# hpb_reva register map
Registers are access not given, no defined reset value unless marked. A register's access mark holds for its fields unless they carry their own. Offsets are from the block's base; lines under a group give offsets from that group; [hi:lo] are bit positions; {n}, {i} and the like mark numbered series; 'fields as' and 'values as' point back to an identical list; <NAME> marks a mode.

## Memory map
0x40039000 HPB size 0x1000 — HyperBus Memory Controller Registers

## HPB — HyperBus Memory Controller Registers
Base 0x40039000
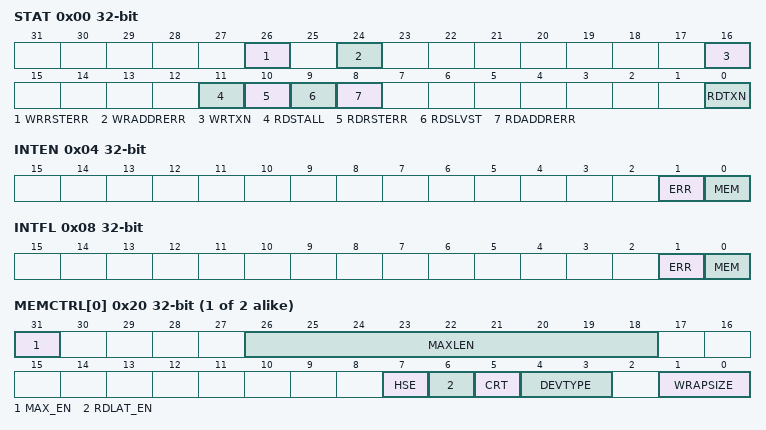
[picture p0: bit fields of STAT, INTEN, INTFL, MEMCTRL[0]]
0x00 STAT — Hyperbus Status Register.
  [26] WRRSTERR — Reset During Write Error. If this field is set a reset orrcured during a write.
    0=normal_op (No error.); 1=err (Memory controller was reset during write operation.)
  [24] WRADDRERR — Write Address Error. If this field is set a write address error orrcured.
    0=normal_op (No error.); 1=err (The write address to external memory is invalid.)
  [16] WRTXN — Write Transaction in Progress
    0=No write transaction currently in progress; 1=Write transaction currently in progress
  [11] RDSTALL — Read Data Stall.
    0=normal_op (Memory Controller operating normally.); 1=stalled (Read transaction is stalled because RDS is low (stalled).)
  [10] RDRSTERR — Reset During Read Error. If this field is set a reset orrcured during a read.
    0=normal_op (No error.); 1=err (Memory controller was reset during read operation.)
  [9] RDSLVST — Read Slave Status.
  [8] RDADDRERR — Read Address Error
    0=normal_op (No error.); 1=err (External read address not responding.)
  [0] RDTXN — Read Transaction in Progress
    0=No read transaction currently in progress; 1=Read transaction currently in progress
0x04 INTEN — Hyperbus Interrupt Enable Register.
  [1] ERR — Enables/disables the HPB error interrupt.
    0=dis (Disable error interrupt.); 1=en (Enable error interrupt.)
  [0] MEM — Hyperbus Memory Interrupt Enable.
    0=dis (Disable interrupt.); 1=en (Enable interrupt.)
0x08 INTFL — Hyperbus Interrupt Flag Register.
  [1] ERR — Error interrupt status flag.
    0=noint (Error interrupt not active.); 1=pending (Error interrupt currently pending.)
  [0] MEM — Hyperbus Memory Status Flag.
    0=noint (Memory interrupt not active.); 1=pending (Memory interrupt currently pending.)
{0x10+4i} MEMBADDR[{i}] (i=0..1) — Hyperbus Memory Base Address Register.
  [31:0] ADDR — Memory base address. This sets the base address of the addressable memory region where the port is mapped. Each address space is 512Mbytes. The lower 24 bits are read only and will always read 0.
{0x20+4i} MEMCTRL[{i}] (i=0..1) — Hyperbus Memory Control Register.
  [31] MAX_EN — Maximum CS# Length Enable.
    0=dis (No configured CS# low time.); 1=en (CS# low time is configured.)
  [26:18] MAXLEN — Maximum Read/Write. Set this field to the CS# low time in terms of clock cycles.
  [7] HSE — Xccela Half Sleep Exit. When half sleep exit is enabled, the CS# line is held low for ten clock cycles. This bit is automatically cleared by hardware when a Half Sleep Exit completes.
    0=dis (Half Sleep Exit disabled.); 1=en (Half Sleep Exit enabled.)
  [6] RDLAT_EN — Xccela Fixed Read Latency Enable. Set this bit to enable Xccela bus Fixed Read Latency. Set this field to match the latency Type configuration in the target PSRAM.
    0=Variable read latency; 1=Fixed read latency
  [5] CRT — Configuration Register Target Select. For HyperRAM and Xccela Bus devices, this field selects between read/write target being the devices memory map or configuration register space. For HyperFlash set this field to 0.
    0=mem_space (Access Memory space.); 1=config_reg (Access Configuration Register space.)
  [4:3] DEVTYPE — Select the memory device type.
    0=hyperFlash; 1=xccela_psram; 2=hyperRAM
  [1:0] WRAPSIZE — The wrap burst length of HyperBus memory. This bit is ignored when the asymmetry cache support bit is 0. When the asymmetry cache support is 1, this bit should be set the same as wrap size of configuration register in HyperBus memory.
    1=64B (64 bytes); 2=16B (16 bytes); 3=32B (32 bytes)
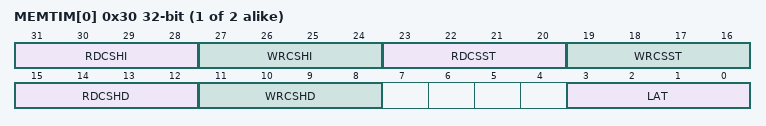
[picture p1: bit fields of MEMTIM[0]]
{0x30+4i} MEMTIM[{i}] (i=0..1) — Hyperbus Memory Timing Register.
  [31:28] RDCSHI — Read Chip Select High Between Operations.
  [27:24] WRCSHI — Write Chip Select High Between Operations.
  [23:20] RDCSST — Read Chip Select Setup Time to Next CK Rising Edge.
  [19:16] WRCSST — Write Chip Select Setup Time to Next CK Rising Edge.
  [15:12] RDCSHD — Read Chip Select Hold after CK falling edge.
  [11:8] WRCSHD — Write Chip Select Hold after CK falling edge.
  [3:0] LAT — RAM Latency.
    0=5clk (5 Clock cycles.); 1=6clk (6 Clock cycles.); 14=3clk (3 Clock cycles.); 15=4clk (4 Clock cycles.)
